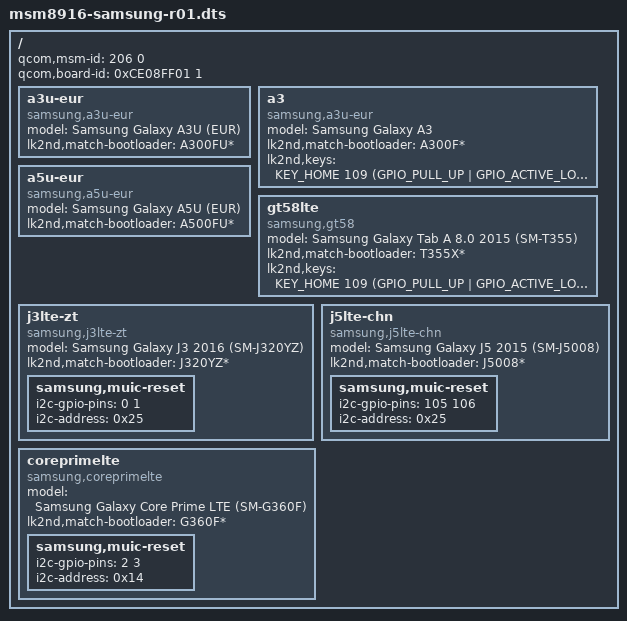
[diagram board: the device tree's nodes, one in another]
// SPDX-License-Identifier: GPL-2.0-only

/dts-v1/;

#include <skeleton.dtsi>
#include <lk2nd.h>

/ {
	// This is used by the bootloader to find the correct DTB
	qcom,msm-id = <206 0>;
	qcom,board-id = <0xCE08FF01 1>;

	// Unfortunately, Samsung uses the same qcom,board-id for all its
	// MSM8916 devices (except for device revisions).
	// Therefore, it will always pick this shared device tree and
	// we need to do more manual work to differentiate the devices.
	a3u-eur {
		model = "Samsung Galaxy A3U (EUR)";
		compatible = "samsung,a3u-eur", "qcom,msm8916", "lk2nd,device";
		lk2nd,match-bootloader = "A300FU*";
	};

	a3 {
		model = "Samsung Galaxy A3";
		compatible = "samsung,a3u-eur", "qcom,msm8916", "lk2nd,device";
		lk2nd,match-bootloader = "A300F*";

		lk2nd,keys = <KEY_HOME 109 (GPIO_PULL_UP | GPIO_ACTIVE_LOW)>;
	};

	a5u-eur {
		model = "Samsung Galaxy A5U (EUR)";
		compatible = "samsung,a5u-eur", "qcom,msm8916", "lk2nd,device";
		lk2nd,match-bootloader = "A500FU*";
	};

	gt58lte {
		model = "Samsung Galaxy Tab A 8.0 2015 (SM-T355)";
		compatible = "samsung,gt58", "qcom,msm8916", "lk2nd,device";
		lk2nd,match-bootloader = "T355X*";

		lk2nd,keys = <KEY_HOME 109 (GPIO_PULL_UP | GPIO_ACTIVE_LOW)>;
	};

	j3lte-zt {
		model = "Samsung Galaxy J3 2016 (SM-J320YZ)";
		compatible = "samsung,j3lte-zt", "qcom,msm8916", "lk2nd,device";
		lk2nd,match-bootloader = "J320YZ*";
		samsung,muic-reset {
			i2c-gpio-pins = <0 1>;
			i2c-address = <0x25>;
		};
	};

	j5lte-chn {
		model = "Samsung Galaxy J5 2015 (SM-J5008)";
		compatible = "samsung,j5lte-chn", "qcom,msm8916", "lk2nd,device";
		lk2nd,match-bootloader = "J5008*";
		samsung,muic-reset {
			i2c-gpio-pins = <105 106>;
			i2c-address = <0x25>;
		};
	};

	coreprimelte {
		// In the downstream dts it is called Samsung ROSSA PROJECT Rev03
		model = "Samsung Galaxy Core Prime LTE (SM-G360F)";
		compatible = "samsung,coreprimelte", "qcom,msm8916", "lk2nd,device";
		lk2nd,match-bootloader = "G360F*";

		samsung,muic-reset {
			i2c-gpio-pins = <2 3>;
			i2c-address = <0x14>;
		};
	};
};
